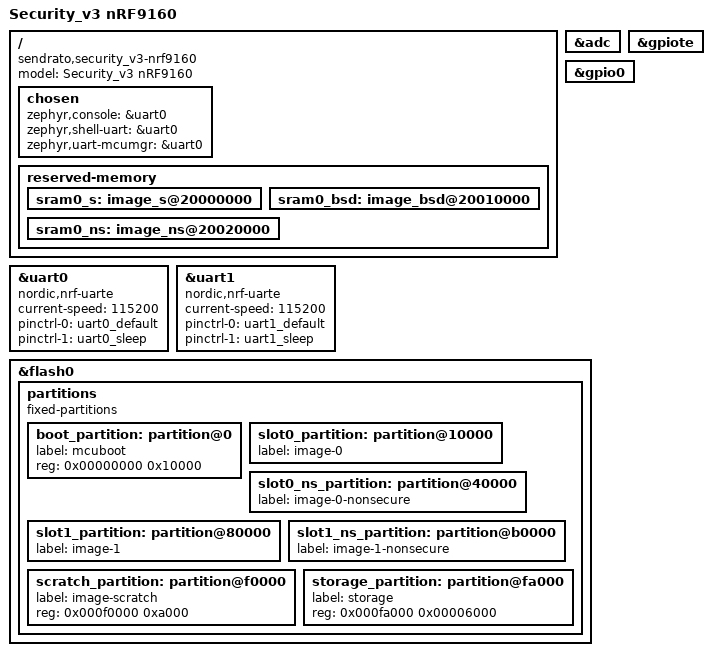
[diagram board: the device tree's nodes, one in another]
/*
 * Copyright (c) 2024, Sendrato.com, All rights reserved.
 *
 * SPDX-License-Identifier: All rights reserved.
 */
#include "security_v3_nrf9160_common-pinctrl.dtsi"

/ {
	model = "Security_v3 nRF9160";
	compatible = "sendrato,security_v3-nrf9160";

	chosen {
		zephyr,console = &uart0;
		zephyr,shell-uart = &uart0;
		zephyr,uart-mcumgr = &uart0;
	};
};

&adc {
	status = "okay";
};

&gpiote {
	status = "okay";
};

&gpio0 {
	status = "okay";
};

&uart0 {
	compatible = "nordic,nrf-uarte";
	current-speed = <115200>;
	status = "okay";
	pinctrl-0 = <&uart0_default>;
	pinctrl-1 = <&uart0_sleep>;
	pinctrl-names = "default", "sleep";
};

&uart1 {
	compatible = "nordic,nrf-uarte";
	current-speed = <115200>;
	status = "okay";
	pinctrl-0 = <&uart1_default>;
	pinctrl-1 = <&uart1_sleep>;
	pinctrl-names = "default", "sleep";
};

&flash0 {
	/*
	 * For more information, see:
	 * http://docs.zephyrproject.org/devices/dts/flash_partitions.html
	 */
	partitions {
		compatible = "fixed-partitions";
		#address-cells = <1>;
		#size-cells = <1>;

		boot_partition: partition@0 {
			label = "mcuboot";
			reg = <0x00000000 0x10000>;
		};
		slot0_partition: partition@10000 {
			label = "image-0";
		};
		slot0_ns_partition: partition@40000 {
			label = "image-0-nonsecure";
		};
		slot1_partition: partition@80000 {
			label = "image-1";
		};
		slot1_ns_partition: partition@b0000 {
			label = "image-1-nonsecure";
		};
		scratch_partition: partition@f0000 {
			label = "image-scratch";
			reg = <0x000f0000 0xa000>;
		};
		storage_partition: partition@fa000 {
			label = "storage";
			reg = <0x000fa000 0x00006000>;
		};
	};
};

/ {

	reserved-memory {
		#address-cells = <1>;
		#size-cells = <1>;
		ranges;

		sram0_s: image_s@20000000 {
			/* Secure image memory */
		};

		sram0_bsd: image_bsd@20010000 {
			/* BSD (shared) memory */
		};

		sram0_ns: image_ns@20020000 {
			/* Non-Secure image memory */
		};
	};
};

/* Include partition configuration file */
#include "security_v3_nrf9160_partition_conf.dts"
